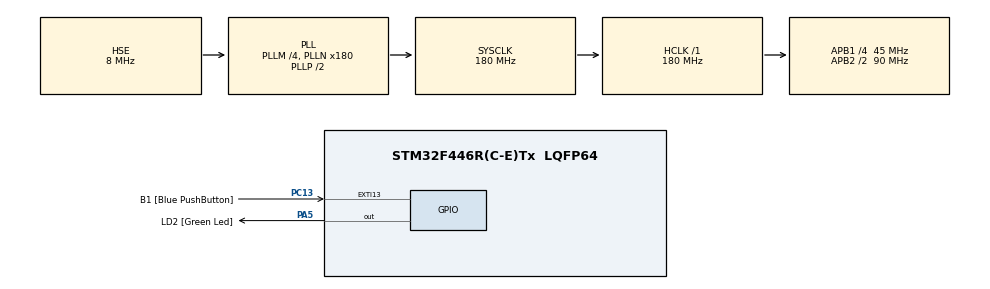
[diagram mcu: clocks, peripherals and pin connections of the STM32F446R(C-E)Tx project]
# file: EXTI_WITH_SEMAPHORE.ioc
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FREERTOS.BinarySemaphores01=semaphore_bt,Dynamic,NULL
FREERTOS.MEMORY_ALLOCATION=0
FREERTOS.Tasks01=th1_led,1,128,th1_led_fun,Default,NULL,Dynamic,NULL,NULL;th2_led,0,128,th2_led_fun,Default,NULL,Dynamic,NULL,NULL;th3_sos,2,128,th3_sos_fun,Default,NULL,Dynamic,NULL,NULL
FREERTOS.configUSE_MALLOC_FAILED_HOOK=1
Mcu.Family=STM32F4
Mcu.Name=STM32F446R(C-E)Tx
Mcu.Package=LQFP64
NVIC.EXTI15_10_IRQn=true\:5\:0\:false\:false\:true\:true\:true\:true
NVIC.PVD_IRQn=true\:5\:0\:false\:false\:true\:true\:true\:true
NVIC.PriorityGroup=NVIC_PRIORITYGROUP_4
NVIC.TIM6_DAC_IRQn=true\:0\:0\:false\:false\:true\:false\:false\:true
NVIC.TimeBase=TIM6_DAC_IRQn
NVIC.TimeBaseIP=TIM6
PA13.GPIO_Label=TMS
PA13.Mode=Serial_Wire
PA13.Signal=SYS_JTMS-SWDIO
PA14.GPIO_Label=TCK
PA14.Mode=Serial_Wire
PA14.Signal=SYS_JTCK-SWCLK
PA2.GPIO_Label=USART_TX
PA2.Signal=USART2_TX
PA3.GPIO_Label=USART_RX
PA3.Signal=USART2_RX
PA5.GPIO_Label=LD2 [Green Led]
PA5.Signal=GPIO_Output
PB3.GPIO_Label=SWO
PB3.Signal=SYS_JTDO-SWO
PC13.GPIO_Label=B1 [Blue PushButton]
PC13.GPIO_ModeDefaultEXTI=GPIO_MODE_IT_FALLING
PC13.Signal=GPXTI13
PC14-OSC32_IN.Signal=RCC_OSC32_IN
PC15-OSC32_OUT.Signal=RCC_OSC32_OUT
PH0-OSC_IN.Mode=HSE-External-Clock-Source
PH0-OSC_IN.Signal=RCC_OSC_IN
PH1-OSC_OUT.Mode=HSE-External-Clock-Source
PH1-OSC_OUT.Signal=RCC_OSC_OUT
ProjectManager.HeapSize=0x200
ProjectManager.StackSize=0x400
ProjectManager.TargetToolchain=STM32CubeIDE
RCC.AHBFreq_Value=180000000
RCC.APB1CLKDivider=RCC_HCLK_DIV4
RCC.APB1Freq_Value=45000000
RCC.APB1TimFreq_Value=90000000
RCC.APB2CLKDivider=RCC_HCLK_DIV2
RCC.APB2Freq_Value=90000000
RCC.APB2TimFreq_Value=180000000
RCC.CortexFreq_Value=180000000
RCC.FLatency-AdvancedSettings=FLASH_LATENCY_5
RCC.HCLKFreq_Value=180000000
RCC.HSE_VALUE=8000000
RCC.HSI_VALUE=16000000
RCC.LSE_VALUE=32768
RCC.PLLM=4
RCC.PLLN=180
RCC.PLLSourceVirtual=RCC_PLLSOURCE_HSE
RCC.SYSCLKFreq_VALUE=180000000
RCC.SYSCLKSource=RCC_SYSCLKSOURCE_PLLCLK
RCC.USBFreq_Value=180000000
RCC.VCOOutputFreq_Value=360000000
VP_FREERTOS_VS_CMSIS_V1.Mode=CMSIS_V1
VP_SYS_VS_tim6.Mode=TIM6
board=NUCLEO-F446RE

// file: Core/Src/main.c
/* USER CODE BEGIN Header */
/**
  ******************************************************************************
  * @file           : main.c
  * @brief          : Main program body
  ******************************************************************************
  * @attention
  *
  * <h2><center>&copy; Copyright (c) 2020 STMicroelectronics.
  * All rights reserved.</center></h2>
  *
  * This software component is licensed by ST under BSD 3-Clause license,
  * the "License"; You may not use this file except in compliance with the
  * License. You may obtain a copy of the License at:
  *                        opensource.org/licenses/BSD-3-Clause
  *
  ******************************************************************************
  */
/* USER CODE END Header */

#include "main.h"
#include "cmsis_os.h"
#include "gpio.h"

void SystemClock_Config(void);
void MX_FREERTOS_Init(void);

int main(void)
{

  /* MCU Configuration--------------------------------------------------------*/

  /* Reset of all peripherals, Initializes the Flash interface and the Systick. */
  HAL_Init();

  /* Configure the system clock */
  SystemClock_Config();

  /* Initialize all configured peripherals */
  MX_GPIO_Init();

  /* Call init function for freertos objects (in freertos.c) */
  MX_FREERTOS_Init();

  /* Start scheduler */
  osKernelStart();

  /* We should never get here as control is now taken by the scheduler */

  /* Infinite loop */
  while (1)
  {

  }
}

void SystemClock_Config(void)
{
  RCC_OscInitTypeDef RCC_OscInitStruct = {0};
  RCC_ClkInitTypeDef RCC_ClkInitStruct = {0};

  /** Configure the main internal regulator output voltage
  */
  __HAL_RCC_PWR_CLK_ENABLE();
  __HAL_PWR_VOLTAGESCALING_CONFIG(PWR_REGULATOR_VOLTAGE_SCALE1);
  /** Initializes the CPU, AHB and APB busses clocks
  */
  RCC_OscInitStruct.OscillatorType = RCC_OSCILLATORTYPE_HSE;
  RCC_OscInitStruct.HSEState = RCC_HSE_BYPASS;
  RCC_OscInitStruct.PLL.PLLState = RCC_PLL_ON;
  RCC_OscInitStruct.PLL.PLLSource = RCC_PLLSOURCE_HSE;
  RCC_OscInitStruct.PLL.PLLM = 4;
  RCC_OscInitStruct.PLL.PLLN = 180;
  RCC_OscInitStruct.PLL.PLLP = RCC_PLLP_DIV2;
  RCC_OscInitStruct.PLL.PLLQ = 2;
  RCC_OscInitStruct.PLL.PLLR = 2;
  if (HAL_RCC_OscConfig(&RCC_OscInitStruct) != HAL_OK)
  {
    Error_Handler();
  }
  /** Activate the Over-Drive mode
  */
  if (HAL_PWREx_EnableOverDrive() != HAL_OK)
  {
    Error_Handler();
  }
  /** Initializes the CPU, AHB and APB busses clocks
  */
  RCC_ClkInitStruct.ClockType = RCC_CLOCKTYPE_HCLK|RCC_CLOCKTYPE_SYSCLK
                              |RCC_CLOCKTYPE_PCLK1|RCC_CLOCKTYPE_PCLK2;
  RCC_ClkInitStruct.SYSCLKSource = RCC_SYSCLKSOURCE_PLLCLK;
  RCC_ClkInitStruct.AHBCLKDivider = RCC_SYSCLK_DIV1;
  RCC_ClkInitStruct.APB1CLKDivider = RCC_HCLK_DIV4;
  RCC_ClkInitStruct.APB2CLKDivider = RCC_HCLK_DIV2;

  if (HAL_RCC_ClockConfig(&RCC_ClkInitStruct, FLASH_LATENCY_5) != HAL_OK)
  {
    Error_Handler();
  }
}

void HAL_TIM_PeriodElapsedCallback(TIM_HandleTypeDef *htim)
{
  if (htim->Instance == TIM6) {
    HAL_IncTick();
  }
}

void Error_Handler(void)
{
}

/************************ (C) COPYRIGHT STMicroelectronics *****END OF FILE****/

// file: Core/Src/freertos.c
/* USER CODE BEGIN Header */
/**
  ******************************************************************************
  * File Name          : freertos.c
  * Description        : Code for freertos applications
  ******************************************************************************
  * @attention
  *
  * <h2><center>&copy; Copyright (c) 2020 STMicroelectronics.
  * All rights reserved.</center></h2>
  *
  * This software component is licensed by ST under Ultimate Liberty license
  * SLA0044, the "License"; You may not use this file except in compliance with
  * the License. You may obtain a copy of the License at:
  *                             www.st.com/SLA0044
  *
  ******************************************************************************
  */
/* USER CODE END Header */

#include "FreeRTOS.h"
#include "task.h"
#include "main.h"
#include "cmsis_os.h"

osThreadId th1_ledHandle;
osThreadId th2_ledHandle;
osThreadId th3_sosHandle;
osSemaphoreId bt_Handle;
osMutexId led_Handle;

void th1_led_fun(void const * argument);
void th2_led_fun(void const * argument);
void th3_sos_fun(void const * argument);

void MX_FREERTOS_Init(void); /* (MISRA C 2004 rule 8.1) */

/* Hook prototypes */
void vApplicationMallocFailedHook(void);

/* USER CODE BEGIN 5 */
__weak void vApplicationMallocFailedHook(void)
{
   /* vApplicationMallocFailedHook() will only be called if
   configUSE_MALLOC_FAILED_HOOK is set to 1 in FreeRTOSConfig.h. It is a hook
   function that will get called if a call to pvPortMalloc() fails.
   pvPortMalloc() is called internally by the kernel whenever a task, queue,
   timer or semaphore is created. It is also called by various parts of the
   demo application. If heap_1.c or heap_2.c are used, then the size of the
   heap available to pvPortMalloc() is defined by configTOTAL_HEAP_SIZE in
   FreeRTOSConfig.h, and the xPortGetFreeHeapSize() API function can be used
   to query the size of free heap space that remains (although it does not
   provide information on how the remaining heap might be fragmented). */
}
/* USER CODE END 5 */

void MX_FREERTOS_Init(void) {

  /* USER CODE BEGIN RTOS_MUTEX */
  /* add mutexes, ... */
	osMutexDef(mutex_led);
    led_Handle = osMutexCreate(osMutex(mutex_led));
  /* USER CODE END RTOS_MUTEX */

  /* Create the semaphores(s) */
  /* definition and creation of semaphore_bt */
  osSemaphoreDef(semaphore_bt);
  bt_Handle = osSemaphoreCreate(osSemaphore(semaphore_bt), 1);

  /* Create the thread(s) */
  /* definition and creation of th1_led */
  osThreadDef(th1_led, th1_led_fun, osPriorityAboveNormal, 0, 128);
  th1_ledHandle = osThreadCreate(osThread(th1_led), NULL);

  /* definition and creation of th2_led */
  osThreadDef(th2_led, th2_led_fun, osPriorityNormal, 0, 128);
  th2_ledHandle = osThreadCreate(osThread(th2_led), NULL);

  /* definition and creation of th3_sos */
  osThreadDef(th3_sos, th3_sos_fun, osPriorityHigh, 0, 128);
  th3_sosHandle = osThreadCreate(osThread(th3_sos), NULL);

}

void th1_led_fun(void const * argument)
{
  /* USER CODE BEGIN th1_led_fun */
  /* Infinite loop */
  for(;;)
  {
	if(osMutexWait(led_Handle,osWaitForever)==osOK){
		uint32_t i = 15;
		while(i--){
		  HAL_GPIO_TogglePin(GPIOA, GPIO_PIN_5);
		  osDelay(700);
		}
		osMutexRelease(led_Handle);
	}
   osDelay(1);
  }
  /* USER CODE END th1_led_fun */
}

void th2_led_fun(void const * argument)
{
  /* USER CODE BEGIN th2_led_fun */
  /* Infinite loop */
	  for(;;)
	    {
	  	if(osMutexWait(led_Handle,osWaitForever)==osOK){
	  		uint32_t i = 15;
	  		while(i--){
	  		  HAL_GPIO_TogglePin(GPIOA, GPIO_PIN_5);
	  		  osDelay(1000);
	  		}
	  		osMutexRelease(led_Handle);
	  	}

       }
	  osDelay(1);
  /* USER CODE END th2_led_fun */
}

void th3_sos_fun(void const * argument)
{
  /* USER CODE BEGIN th3_sos_fun */
   osSemaphoreWait(bt_Handle,0);
	/* Infinite loop */
  for(;;)
  {
   if(osSemaphoreWait(bt_Handle, osWaitForever) == osOK){
   uint32_t i = 100;
   while(i--){
	   HAL_GPIO_TogglePin(GPIOA, GPIO_PIN_5);
	   osDelay(100);
    }
   }
   osDelay(1);
  }
  /* USER CODE END th3_sos_fun */
}

/* USER CODE BEGIN Application */
void HAL_GPIO_EXTI_Callback(uint16_t GPIO_Pin) {
	if (GPIO_Pin == B1_Pin) {
		osSemaphoreRelease(bt_Handle);
	}
}
/* USER CODE END Application */

/************************ (C) COPYRIGHT STMicroelectronics *****END OF FILE****/
